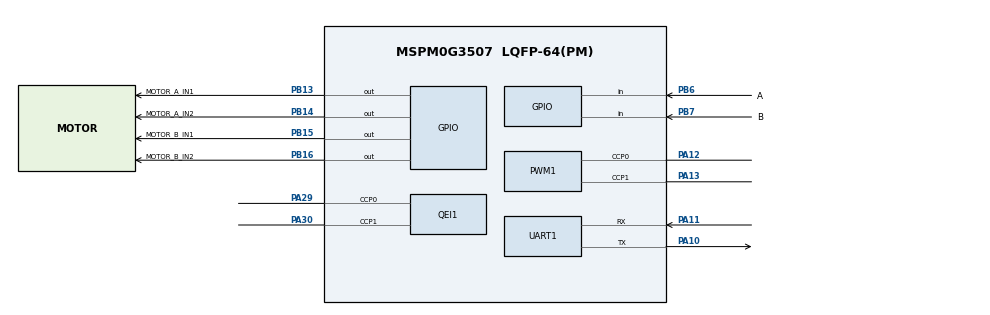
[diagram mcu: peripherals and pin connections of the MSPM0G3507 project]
/**
 * 天猛星 MSPM0G3507 工作台基线配置（CCS / SysConfig 1.2x，MSPM0 SDK 2.11）。
 * 【未验证】手写，按 TI 例程格式；未在 SysConfig GUI 打开过、未上板。引脚与 ../board.yaml 一致，
 * 由 `make check` 中 `syscfg_import.py --check ../board.yaml` 比对。打开后若 SysConfig 报冲突，以 GUI 为准改好再回写 board.yaml。
 */
//@cliArgs --device "MSPM0G350X" --package "LQFP-64(PM)" --part "Default"
//@v2CliArgs --device "MSPM0G3507" --package "LQFP-64(PM)"
// @cliArgs --rtos nortos

const GPIO   = scripting.addModule("/ti/driverlib/GPIO", {}, false);
const GPIO1  = GPIO.addInstance();
const GPIO2  = GPIO.addInstance();
const GPIO3  = GPIO.addInstance();
const GPIO4  = GPIO.addInstance();
const GPIO5  = GPIO.addInstance();
const PWM    = scripting.addModule("/ti/driverlib/PWM", {}, false);
const PWM1   = PWM.addInstance();
const QEI    = scripting.addModule("/ti/driverlib/QEI", {}, false);
const QEI1   = QEI.addInstance();
const SYSCTL = scripting.addModule("/ti/driverlib/SYSCTL");
const TIMER  = scripting.addModule("/ti/driverlib/TIMER", {}, false);
const TIMER1 = TIMER.addInstance();
const UART   = scripting.addModule("/ti/driverlib/UART", {}, false);
const UART1  = UART.addInstance();

GPIO1.$name                         = "GPIO_MOTOR_A_IN1";
GPIO1.associatedPins[0].$name       = "MOTOR_A_IN1";
GPIO1.associatedPins[0].pin.$assign = "PB13";
GPIO2.$name                         = "GPIO_MOTOR_A_IN2";
GPIO2.associatedPins[0].$name       = "MOTOR_A_IN2";
GPIO2.associatedPins[0].pin.$assign = "PB14";
GPIO3.$name                         = "GPIO_MOTOR_B_IN1";
GPIO3.associatedPins[0].$name       = "MOTOR_B_IN1";
GPIO3.associatedPins[0].pin.$assign = "PB15";
GPIO4.$name                         = "GPIO_MOTOR_B_IN2";
GPIO4.associatedPins[0].$name       = "MOTOR_B_IN2";
GPIO4.associatedPins[0].pin.$assign = "PB16";

GPIO5.$name                              = "ENC_MOTOR_B";
GPIO5.associatedPins.create(2);
GPIO5.associatedPins[0].$name            = "A";
GPIO5.associatedPins[0].direction        = "INPUT";
GPIO5.associatedPins[0].interruptEn      = true;
GPIO5.associatedPins[0].polarity         = "RISE_FALL";
GPIO5.associatedPins[0].pin.$assign      = "PB6";
GPIO5.associatedPins[1].$name            = "B";
GPIO5.associatedPins[1].direction        = "INPUT";
GPIO5.associatedPins[1].interruptEn      = true;
GPIO5.associatedPins[1].polarity         = "RISE_FALL";
GPIO5.associatedPins[1].pin.$assign      = "PB7";

PWM1.$name                      = "PWM_TIMG0";
PWM1.timerCount                 = 1600;      /* 32 MHz / 1600 = 20 kHz（假定 BUSCLK 32 MHz、不分频）*/
PWM1.peripheral.$assign         = "TIMG0";
PWM1.peripheral.ccp0Pin.$assign = "PA12";
PWM1.peripheral.ccp1Pin.$assign = "PA13";

QEI1.$name                      = "ENC_MOTOR_A";
QEI1.peripheral.$assign         = "TIMG8";
QEI1.peripheral.ccp0Pin.$assign = "PA29";
QEI1.peripheral.ccp1Pin.$assign = "PA30";

SYSCTL.forceDefaultClkConfig = true;

TIMER1.$name              = "TIMER_CTRL";
TIMER1.profile            = "Basic_Periodic";
TIMER1.timerClkPrescale   = 32;              /* 1 MHz */
TIMER1.timerPeriod        = "1 ms";
TIMER1.interrupts         = ["ZERO"];
TIMER1.peripheral.$assign = "TIMG7";

UART1.$name                    = "UART_LINK";
UART1.targetBaudRate           = 115200;
UART1.enabledInterrupts        = ["RX"];
UART1.peripheral.$assign       = "UART0";
UART1.peripheral.rxPin.$assign = "PA11";
UART1.peripheral.txPin.$assign = "PA10";
